# psc3_p8 register map
Vendor: Infineon Technologies; Series: PSC3_P8; File version: 1.0
CPU: CM33 r0p1, little endian, MPU, FPU, DSP, VTOR, 3 interrupt priority bits, 143 interrupts
Registers are 32-bit, read-write, reset 0x0 unless marked. A register's access mark holds for its fields unless they carry their own. Offsets are from the block's base; [hi:lo] are bit positions; lines under a group give offsets from that group; {n}, {i} and the like mark numbered series.

## PPCA_CPUSS_CNFG
Base 0x43080000
{0x0+0x10000*i} PPCA_MXCM33[{i}] (i=0..1) group — MXCM33-0/1
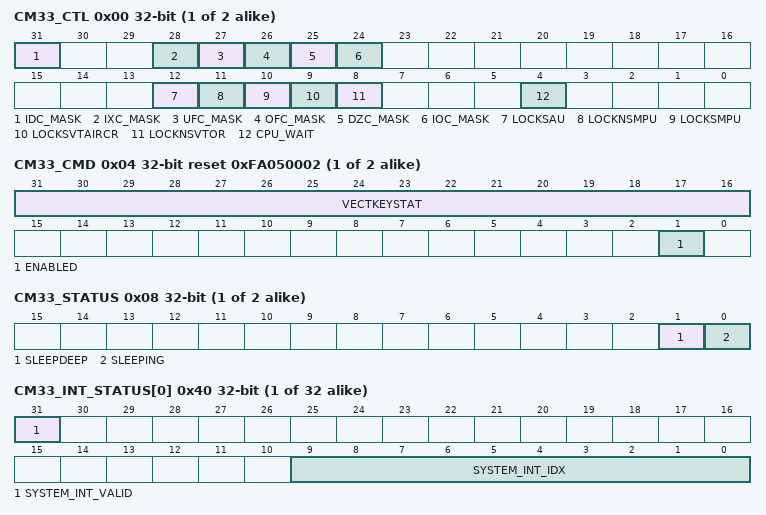
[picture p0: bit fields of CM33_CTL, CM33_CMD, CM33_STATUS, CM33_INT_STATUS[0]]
  0x00 CM33_CTL — Control
    [31] IDC_MASK
    [28] IXC_MASK
    [27] UFC_MASK
    [26] OFC_MASK
    [25] DZC_MASK
    [24] IOC_MASK — CPU floating point unit (FPU) exception mask for the CPU's FPCSR.IOC 'invalid operation' exception condition: '0': The CPU's exception condition does NOT activate the CPU's floating point interrupt. '1': the CPU's exception condition activates the CPU's floating point interrupt. Note: the ARM architecture does NOT support FPU exceptions; i.e. there is no precise FPU exception handler. Instead, FPU conditions are captured in the CPU's FPCSR register and the conditions are provided as CPU interface signals. The interface signals are 'masked' with the fields provided by this register (CM33_CTL). The 'masked' signals are reduced/OR-ed into a single CPU floating point interrupt signal. The associated CPU interrupt handler allows for imprecise handling of FPU exception conditions. Note: the CPU's FPCSR exception conditions are 'sticky'. Typically, the CPU FPU interrupt handler will clear the exception condition(s) to '0'. Note: by default, the FPU exception masks are '0'. Therefore, FPU exception conditions will NOT activate the CPU's floating point interrupt.
    [12] LOCKSAU
    [11] LOCKNSMPU
    [10] LOCKSMPU
    [9] LOCKSVTAIRCR
    [8] LOCKNSVTOR
    [4] CPU_WAIT
  0x04 CM33_CMD reset 0xFA050002 — Command
    [31:16] VECTKEYSTAT ro — Register key (to prevent accidental writes). - Should be written with a 0x05fa key value for the write to take effect. - Always reads as 0xfa05.
    [1] ENABLED — Processor enable: '0': Disabled. Processor clock is turned off and reset is activated. After SW clears this field to '0', HW automatically sets this field to '1'. This effectively results in a CM33 reset, followed by a CM33 warm boot. '1': Enabled. Note: The intent is that this bit is modified only through an external probe or by the other CM33 while this CM33 is in Sleep or DeepSleep power mode. If this field is cleared to '0' by this CM33 itself, it should be done under controlled conditions (such that undesirable side effects can be prevented). Note: The CM33 CPU has a AIRCR.SYSRESETREQ register field that allows the CM33 to reset the complete device (ENABLED only disables/enables the CM33), resulting in a warm boot. This CPU register field has similar 'built-in protection' as this register to prevent accidental system writes (the upper 16-bits of the register need to be written with a 0x05fa key value; see CPU user manual for more details).
  0x08 CM33_STATUS ro — Status
    [1] SLEEPDEEP — Specifies if the CPU is in Sleep or DeepSleep power mode. See SLEEPING field.
    [0] SLEEPING — Specifies if the CPU is in Active, Sleep or DeepSleep power mode: - Active power mode: SLEEPING is '0'. - Sleep power mode: SLEEPING is '1' and SLEEPDEEP is '0'. - DeepSleep power mode: SLEEPING is '1' and SLEEPDEEP is '1'.
  {0x40+4j} CM33_INT_STATUS[{j}] (j=0..15) ro (reset mask 0x80000000) — CM33 interrupt status
    [31] SYSTEM_INT_VALID — Valid indication for SYSTEM_INT_IDX. When '0', no system interrupt for CPU interrupt 0 is valid/activated.
    [9:0] SYSTEM_INT_IDX — Lowest CM33 activated system interrupt index for given CPU interrupt. Multiple system interrupts can be mapped on the same CPU interrupt. The selected system interrupt is the system interrupt with the lowest system interrupt index that has an activated interrupt request at the time of the fetch (system_interrupts[SYSTEM_INT_IDX] is '1'). The CPU interrupt handler SW can read SYSTEM_INT_IDX to determine the system interrupt that activated the handler.
  {0x80+4j} CM33_NMI_CTL[{j}] (j=0..3) reset 0x3FF — CM33 NMI control
    [9:0] SYSTEM_INT_IDX — System interrupt select for CPU NMI. The reset value ('1023') ensures that the CPU NMI is NOT connected to any system interrupt after DeepSleep reset.
  0xC0 CM33_EVENT_CTL — CM33 event control
    [4:0] MASK — One mask bit for each CPU (other than itself). 0: Mask is not set. 1: RX event from the corresponding CPU is masked. Bit 0: Other CM33 CPU event Bit 1: CM55_0 CPU event Bit 2: CM55_1 CPU event Bit 3: CM55_2 CPU event Bit 4: CM55_3 CPU event
  0x1000 CM33_S_VECTOR_TABLE_BASE — CM33 secure vector table base
    [31:7] ADDR25 — Address of CM33 secure vector table to be used at reset. Default value: ADDR25: 0x0200000 if PROM is present (points to Secure ROM start address i.e. 0x1000_0000). ADDR25: 0x0680000 if PROM is not present (points to Secure RAMC0 start address i.e. 0x3400_0000).
  0x1004 CM33_NS_VECTOR_TABLE_BASE — CM33 non-secure vector table base
    [31:7] ADDR25 — Address of CM33 non-secure vector table to be used at reset. Default value: ADDR25: 0x0000000 if PROM is present (points to Non-Secure ROM start address i.e. 0x0000_0000). ADDR25: 0x0480000 if PROM is not present (points to Non-Secure RAMC0 start address i.e. 0x2400_0000).
  0x2000 CM33_PC_CTL — CM33 protection context control
    [3:0] VALID — Valid fields for the protection context handler CM33_PCi_HANDLER registers: Bit 0: Valid field for CM33_PC0_HANDLER. Bit 1: Valid field for CM33_PC1_HANDLER. Bit 2: Valid field for CM33_PC2_HANDLER. Bit 3: Valid field for CM33_PC3_HANDLER.
  0x2040 CM33_PC0_HANDLER — CM33 protection context 0 handler
    [31:0] ADDR — Address of the protection context 0 handler. This field is used to detect entry to Cypress 'trusted' code through an exception/interrupt.
  {0x20C0+0x40*j} CM33_PC{j}_HANDLER (j=1..3) — CM33 protection context {j} handler
    [31:0] ADDR — Address of the protection context {j} handler.
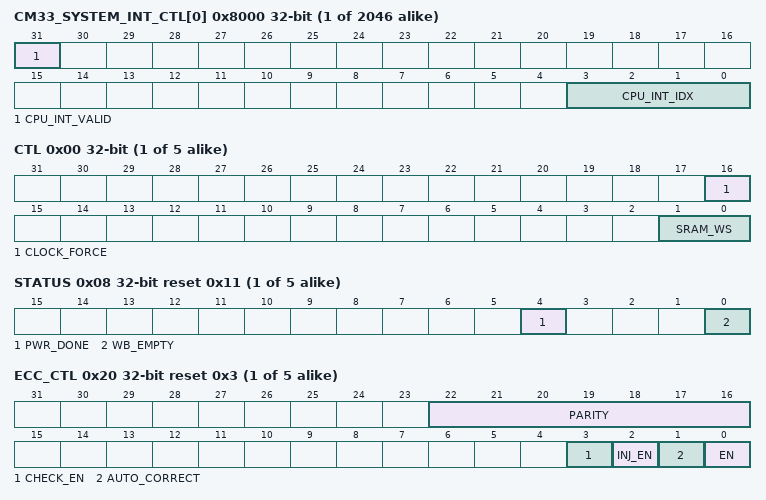
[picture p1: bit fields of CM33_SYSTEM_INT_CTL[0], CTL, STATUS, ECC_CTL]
  {0x8000+4j} CM33_SYSTEM_INT_CTL[{j}] (j=0..1022) (reset mask 0x80000000) — CM33 system interrupt control
    [31] CPU_INT_VALID — Interrupt enable: '0': Disabled. The system interrupt will NOT be mapped to any CPU interrupt. '1': Enabled. The system interrupt is mapped on CPU interrupt CPU_INT_IDX. Note: the CPUs have dedicated XXX_SYSTEM_INT_CTL registers. In other words, the CPUs can use different CPU interrupts for the same system interrupt. However, typically only one of the CPUs will have the ENABLED field of a specific system interrupt set to '1'.
    [3:0] CPU_INT_IDX — CPU interrupt index (legal range [0, 15]). This field specifies to which CPU interrupt the system interrupt is mapped. E.g., if CPU_INT_IDX is '6', the system interrupt is mapped to CPU interrupt '6'. Note: it is possible to map multiple system interrupts to the same CPU interrupt. It is advised to assign different priorities to the CPU interrupts and to assign system interrupts to CPU interrupts accordingly. Note: CPU_INT_IDX register width is derived from mxcm33 parameter IRQ_IDX_WIDTH. IRQ_IDX_WIDTH = (CM33_INT_NR == 16) ? 4 : 3
{0x20000+0x10000*i} RAMC[{i}] (i=0..4) group — RAMC0/1/2
  0x00 CTL — Control
    [16] CLOCK_FORCE — Force EAM clock gating to be always ON. 0: Disabled 1: Enabled This bit provides fail safe mechanism for dynamic clock gating added on EAM block.
    [1:0] SRAM_WS — Wait states.
      {v}=WS_{v} (N/A) (v=0..3)
  0x08 STATUS ro reset 0x11
    [4] PWR_DONE — After a PWR_MACRO_CTL.OFF change this flag indicates if the new power mode has taken effect or not. 1: Indicates change is effective; 0: Indicates change is in progress;
    [0] WB_EMPTY — Write buffer empty. This information is used when entering DeepSleep power mode: WB_EMPTY must be '1' before a transition to system DeepSleep power mode. '0': Write buffer NOT empty. '1': Write buffer empty. Note: the SRAM controller write buffer is only used when ECC checking is enabled. (RAMi_CTL.ECC_EN is '1').
  0x20 ECC_CTL reset 0x3 — ECC control
    [22:16] PARITY — Injected parity.
    [3] CHECK_EN — ECC checking enable: '0': Disabled. No ECC checking and associated bus errors. No fault reporting. Intended for SRAM initialization. '1': Enabled. Note: This field is ignored when EN is '0'.
    [2] INJ_EN — ECC parity injection: '0': Disabled. '1': Enabled. Instead of calculating the parity from the transfer's write data, the parity is taken from PARITY upon a match of the transfer's write address with ECC_MATCH.WORD_ADDR (no match is performed on the transfer's write strobes/mask). Note: Parity injection invalidates the write buffer for this word address. If only a part of 64-bit data word is written AND consistency should be maintained, STATUS.ALL_WB_EMPTY is '1' should be checked before. Note: This field is ignored when EN is '0'.
    [1] AUTO_CORRECT — ECC auto correction: '0': Disabled. Corrected ECC errors are ONLY HW corrected 'on-the-fly' (not corrected in the SRAM). Fault reporting is enabled. '1': Enabled. Correctable ECC errors are HW corrected 'on-the-fly' and in the SRAM, without CPU intervention. Fault reporting is enabled. Note: This field is ignored when EN is '0' or when CHECK_EN is '0'.
    [0] EN — ECC enable: '0': Disabled. '1': Enabled.
      0=ECC_DISABLED (N/A); 1=ECC_ENABLED (N/A)
  0x24 ECC_STATUS0 ro reset not defined
    [31:0] ADDR — ECC error address. This register captures the address location when ECC error happens.
  0x28 ECC_STATUS1 ro reset not defined
    [6:0] SYNDROME — This register captures the ECC syndrome when ECC error happens.
  0x104 ECC_MATCH
    [24:0] WORD_ADDR — Specifies the word address where an error will be injected. - On a write transfer to this SRAM address and when the ECC_CTL.INJ_EN bit is '1', the parity (ECC_CTL.PARITY) is injected.
  0x200 PWR_MACRO_CTL — SRAM power partition power control
    [31:0] OFF — Each bit represent the individual RAM power partition power state. One bit for each macro of RAM controller when all 32 bits are populated as 32 independent power partitions. 0: Macros in power partion is to be powered-ON 1: Macros in power partion is to be powered-OFF Note 1: it is not allowed to disable a macro during access to its address range. Note 2: it is not allowed to disable few macros while enable others in the same AHB write transaction. It is mandatory to check for STATUS.PWR_DONE to become 1 once this PWR_MACRO_DTL register contents are changed to ensure SRAM mode transition is completed successfully.
  0x240 PWR_MACRO_CTL_LOCK reset 0x3 — SRAM power partition power control Lock
    [1:0] PWR_MACRO_CTL_LOCK — Prohibits Read/Write access to PWR_MACRO_CTL register when this field is not equal to 0. Requires at least two different writes to unlock. Note that this field is 2 bits to force multiple writes only. By default AHB reads/writes to PWR_MACRO_CTL register are locked.
      0=NO_CHG (No effect); 1=CLR0 (Clears bit 0); 2=CLR1 (Clears bit 1); 3=SET01 (Sets both bits 0 and 1)
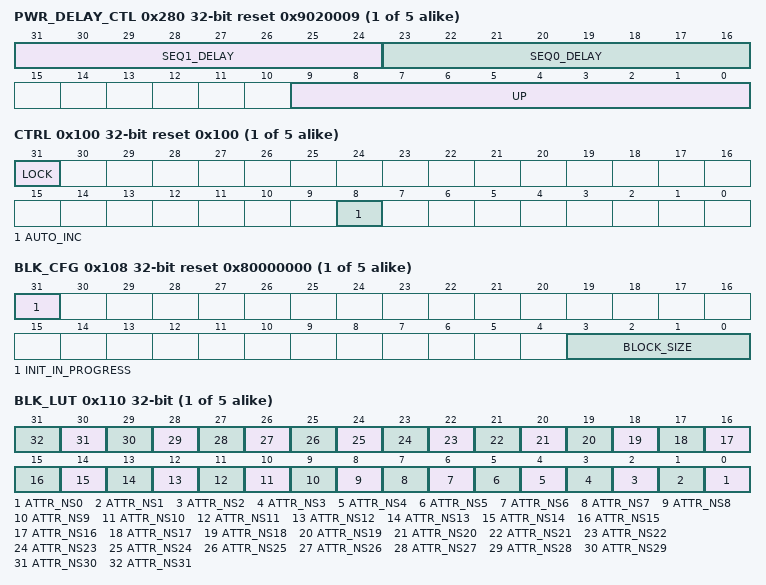
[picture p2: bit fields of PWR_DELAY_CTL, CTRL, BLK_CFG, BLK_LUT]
  0x280 PWR_DELAY_CTL reset 0x9020009 — SRAM power switch power up & sequence delay
    [31:24] SEQ1_DELAY — Number of IMO clock cycles delay needed for sequence-1 of SRAM power transition
    [23:16] SEQ0_DELAY — Number of IMO clock cycles delay needed for sequence-0 of SRAM power transition
    [9:0] UP — Number of IMO clock cycles delay needed after power domain power up
  0x4000 MPC group — MPC Memory Protection Controller registers
    0x00 CFG — Config register with error response, RegionID PPC_MPC_MAIN is the security owner PC. The error response configuration is located in CFG.RESPONSE, only one such configuration exists applying to all protection contexts in the system.
      [4] RESPONSE — Response Configuration for Security and PC violations 0: Read-Zero Write Ignore (RAZ/WI) 1: Bus Error
    0x100 CTRL reset 0x100 — Control register with lock bit and auto-increment only (Separate CTRL for each PC depends on access_pc)
      [31] LOCK write-1-sets — Security lockdown for this protection context. Software can set this bit but not clear it once set. When set, write operations to BLK_LUT are not possible from this protection context. Setting LOCK also blocks writes to CTRL itself (for that PC copy). All writes are ignored.
      [8] AUTO_INC — Auto-increment BLK_IDX by 1 for this protection context as a side effect of each read/write access to BLK_LUT
    0x104 BLK_MAX ro — Max value of block-based index register
      [31:0] VALUE — Maximum value of block-based index register. The number and size blocks in an MPC is design time configurable and for embedded memories defaults to covering the entire memory using 4kB blocks; See product datasheet for details on protection of external memories.
    0x108 BLK_CFG ro reset 0x80000000 — Block size & initialization in progress
      [31] INIT_IN_PROGRESS — During initialization INIT_IN_PROGRESS is '1' and MMIO register accesses to BLK_LUT is blocked (BLK_IDX increment is also ignored). The block attributes are retained in DeepSleep (and obviously Active) power mode. Initialization is only required from a power mode in which the block attributes are not retained. E.g., initialization is required for a cold boot (after a Power-on-Reset). HW initializes the block attributes: the NS attributes are set to '0' (secure), the R attributes are set to '1' (read access allowed) and the W attributes are set to '1' (write access allowed). During initialization, the MPC supports memory accesses (memory accesses are NOT blocked) with the initialization block attribute values as mentioned above. This e.g. allows MPC initialization to proceed in parallel with boot program memory accesses (as opposed to serializing the two), improving device boot time.
      [3:0] BLOCK_SIZE — Block size of individually protected blocks (0: 32B, 1: 64B, ... up to 15: 1MB) Block size= (1<<(BLOCK_SIZE+5)) The number and size blocks in an MPC is design time configurable and for embedded memories defaults to covering the entire memory using 4kB blocks; see product datasheet for details on protection of external memories.
    0x10C BLK_IDX — Index of 32-block group accessed through BLK_LUT (Separate IDX for each PC depending on access_pc)
      [31:0] VALUE — Index value for accessing block-based lookup table using BLK_LUT. Programming out of LUT range is an user error and it loops back to '0' once overflow occurs.
    0x110 BLK_LUT — NS status for 32 blocks at BLK_IDX with PC=<access_pc>
      [n] ATTR_NS{n} (n=0..31) — NS bit for block {n} based on BLK_IDX
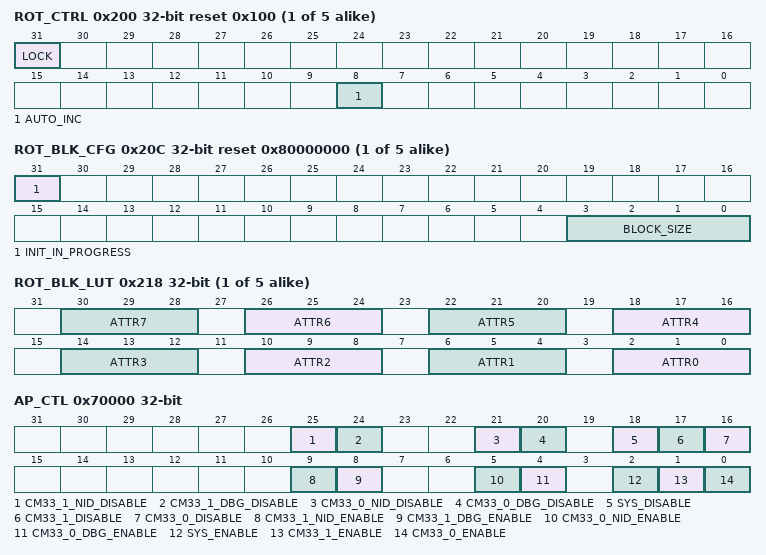
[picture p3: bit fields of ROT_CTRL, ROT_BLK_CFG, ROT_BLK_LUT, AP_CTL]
    0x200 ROT_CTRL reset 0x100 — Control register with lock bit and auto-increment only
      [31] LOCK write-1-sets — Security lockdown for the root-of-trust configuration registers. Software can set this bit but not clear it once set. When set, write operations to ROT_BLK_LUT are not possible. Write is ignored.
      [8] AUTO_INC — Auto-increment BLK_IDX by 1 for each read/write of ROT_BLK_LUT
    0x208 ROT_BLK_MAX ro — Max value of block-based index register for ROT
      [31:0] VALUE — Maximum value of block-based index register. The number and size blocks in an MPC is design time configurable and for embedded memories defaults to covering the entire memory using 4kB blocks; see product datasheet for details on protection of external memories.
    0x20C ROT_BLK_CFG ro reset 0x80000000 — Same as BLK_CFG
      [31] INIT_IN_PROGRESS — During initialization INIT_IN_PROGRESS is '1' and MMIO register accesses to ROT_BLK_LUT is RAZWI. The block attributes are retained in DeepSleep (and obviously Active) power mode. Initialization is only required from a power mode in which the block attributes are not retained. E.g., initialization is required for a cold boot (after a Power-on-Reset). HW initializes the block attributes: the NS attributes are set to '0' (secure), the R attributes are set to '1' (read access allowed) and the W attributes are set to '1' (write access allowed). During initialization, the MPC supports memory accesses (memory accesses are NOT blocked) with the initialization block attribute values as mentioned above. This e.g. allows MPC initialization to proceed in parallel with boot program memory accesses (as opposed to serializing the two), improving device boot time.
      [3:0] BLOCK_SIZE — Block size of individually protected blocks (0: 32B, 1: 64B, ...up to 15:1MB) Block size= (1<<(BLOCK_SIZE+5)) The number and size blocks in an MPC is design time configurable and for embedded memories defaults to covering the entire memory using 4kB blocks; see product datasheet for details on protection of external memories.
    0x210 ROT_BLK_IDX — Index of 8-block group accessed through ROT_BLK_LUT_*
      [31:0] VALUE — Index value for accessing block-based lookup table using ROT_BLK_LUT. Programming out of LUT range is an user error and it loops back to '0' once overflow occurs.
    0x214 ROT_BLK_PC — Protection context of 8-block group accesses through ROT_BLK_LUT
      [3:0] PC — Specify PC values for ROT_BLK_IDX and ROT_BLK_LUT
    0x218 ROT_BLK_LUT — (R,W,NS) bits for 8 blocks at ROT_BLK_IDX for PC=ROT_BKL_PC
      [4n+2:4n] ATTR{n} (n=0..7) — W/R/NS bits for block {n} indicated by ROT_BLK_IDX for ROT_BLK_PC PC
0x70000 AP_CTL — Access port control
  [25] CM33_1_NID_DISABLE write-1-sets — Refer CM33_0_NID_DISABLE description.
  [24] CM33_1_DBG_DISABLE write-1-sets — Refer CM33_0_DBG_DISABLE description.
  [21] CM33_0_NID_DISABLE write-1-sets — Disable Non-invasive debug for CM33_0. '1': Disables all trace and non-invasive debug features. '0': Enables all trace and non-invasive debug features. Typically, this field is set by the Cypress boot code with information from eFUSE. The non-invasive debug is only enabled when CM33_0_NID_DISABLE is '0' and CM33_0_NID_ENABLE is '1'.
  [20] CM33_0_DBG_DISABLE write-1-sets — Disable Invasive debug for CM33_0. '1': Disables all halt-mode and invasive debug features. '0': Enables invasive debug features. Typically, this field is set by the Cypress boot code with information from eFUSE. The invasive debug is only enabled when CM33_0_DBG_DISABLE is '0' and CM33_0_DBG_ENABLE is '1'.
  [18] SYS_DISABLE write-1-sets — Disables the system AP interface: '0': Enabled. '1': Disabled. Typically, this field is set by the Cypress boot code with information from eFUSE. The access port is only enabled when SYS_DISABLE is '0' and SYS_ENABLE is '1'.
  [17] CM33_1_DISABLE write-1-sets — Disables the CM33_1 AP interface: '0': Enabled. '1': Disabled. Typically, this field is set by the Cypress boot code with information from eFUSE. The access port is only enabled when CM33_DISABLE is '0' and CM33_ENABLE is '1'.
  [16] CM33_0_DISABLE write-1-sets — Disables the CM33_0 AP interface: '0': Enabled. '1': Disabled. Typically, this field is set by the Cypress boot code with information from eFUSE. The access port is only enabled when CM0_DISABLE is '0' and CM0_ENABLE is '1'.
  [9] CM33_1_NID_ENABLE — Refer CM33_0_NID_ENABLE.
  [8] CM33_1_DBG_ENABLE — Refer CM33_0_DBG_ENABLE.
  [5] CM33_0_NID_ENABLE — Non-invasive debug enable for CM33_0. '0': Disables all trace and non-invasive debug features. '1': Enables all trace and non-invasive debug features.
  [4] CM33_0_DBG_ENABLE — Invasive debug enable for CM33_0. '0': Disables all halt-mode and invasive debug features. '1': Enables invasive debug features.
  [2] SYS_ENABLE — Enables the system AP interface: '0': Disabled. '1': Enabled.
  [1] CM33_1_ENABLE — Enables the CM33_1 AP interface: '0': Disabled. '1': Enabled.
  [0] CM33_0_ENABLE — Enables the CM33_0 AP interface: '0': Disabled. '1': Enabled.
0x70004 MP_CTL — Master Port Access control
  [0] PPCA_MS_TIMEOUT_ENABLE — Enables the PPCA Master Port Timeout Access control: '0': Disabled. '1': Enabled.
{0x78000+0x1000*i} RAMC_PPU[{i}] (i=0..4) group — Power Policy Unit Registers for System RAM
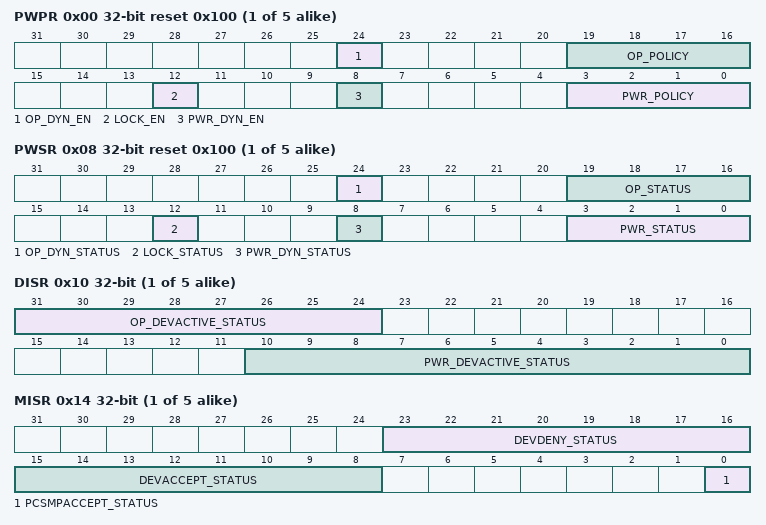
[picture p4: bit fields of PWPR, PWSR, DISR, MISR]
  0x00 PWPR reset 0x100 — Power Policy Register
    [24] OP_DYN_EN
    [19:16] OP_POLICY
    [12] LOCK_EN
    [8] PWR_DYN_EN — Power mode dynamic transition enable. When this bit is set to 1 dynamic transitions are enabled for power modes, allowing transitions to be initiated by changes on power mode DEVACTIVE inputs.
    [3:0] PWR_POLICY — Power mode policy. When static power mode transitions are enabled, PWR_DYN_EN is set to 0, this is the target power mode for the PPU. When dynamic power mode transitions are enabled, PWR_DYN_EN is set to 1, this is the minimum power mode for the PPU. This PPU supports the following modes: OFF(0), MEM_RET(2), ON(8). Do not use WARM_RST(9) or other unsupported modes.
  0x04 PMER — Power Mode Emulation Register
    [0] EMU_EN
  0x08 PWSR ro reset 0x100 — Power Status Register
    [24] OP_DYN_STATUS
    [19:16] OP_STATUS
    [12] LOCK_STATUS
    [8] PWR_DYN_STATUS — Power mode dynamic transition status. When set to 1 power mode dynamic transitions are enabled. There might be a delay in dynamic transitions becoming active or inactive if the PPU is transitioning when PWR_DYN_EN is programmed.
    [3:0] PWR_STATUS — Power mode status. These bits reflect the current power mode of the PPU. See PPU_PWPR.PWR_POLICY for power mode enumeration.
  0x10 DISR ro — Device Interface Input Current Status Register
    [31:24] OP_DEVACTIVE_STATUS
    [10:0] PWR_DEVACTIVE_STATUS — Status of the power mode DEVACTIVE inputs. There is one bit for each device interface Q-Channel DEVQACTIVE. For example, bit 0 is for Q-channel device 0 DEVQACTIVE. Refer to PPU_IDR0.DEVCHAN for device channel enumeration.
  0x14 MISR ro — Miscellaneous Input Current Status Register
    [23:16] DEVDENY_STATUS — Status of the device interface DEVDENY inputs. There is one bit for each device interface DEVQDENY. For example, bit 16 is for Q-Channel 0 DEVQDENY, and bit 17 for Q-Channel 1 DEVQDENY. Refer to PPU_IDR0.DEVCHAN for device channel enumeration.
    [15:8] DEVACCEPT_STATUS — Status of the device interface DEVACCEPT inputs. There is one bit for each device interface DEVQACCEPTn. For example, bit 8 is for Q-Channel 0 DEVQACCEPTn and bit 9 for Q-Channel 1 DEVQACCEPTn. Refer to PPU_IDR0.DEVCHAN for device channel enumeration.
    [0] PCSMPACCEPT_STATUS — The status of the PCSMPACCEPT input.
  0x18 STSR ro — Stored Status Register
    [7:0] STORED_DEVDENY
  0x1C UNLK — Unlock register
    [0] UNLOCK
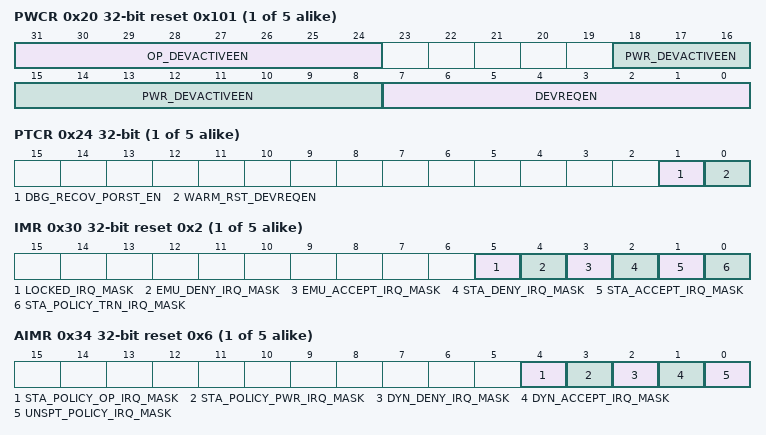
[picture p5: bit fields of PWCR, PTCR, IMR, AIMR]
  0x20 PWCR reset 0x101 — Power Configuration Register
    [31:24] OP_DEVACTIVEEN
    [18:8] PWR_DEVACTIVEEN — These bits enable the power mode DEVACTIVE inputs. When a bit is to 1 the related DEVACTIVE input is enabled, when set to 0 it is disabled. All available bits are reset to 1. There is one bit for each device interface Q-Channel DEVQACTIVE. For example, bit 8 is for the Q-Channel 0 DEVQACTIVE, and bit 9 for the Q-Channel 1 DEVQACTIVE. Refer to PPU_IDR0.DEVCHAN for device channel enumeration.
    [7:0] DEVREQEN — When set to 1 enables the device interface handshake for transitions. All available bits are reset to 1. There is one bit for each device interface channel. For example, bit 0 is for Q-Channel 0, and bit 1 is for Q-Channel 1. Refer to PPU_IDR0.DEVCHAN for device channel enumeration.
  0x24 PTCR — Power Mode Transition Configuration Register
    [1] DBG_RECOV_PORST_EN
    [0] WARM_RST_DEVREQEN — Transition behavior between ON and WARM_RST. This bit should not be modified when the PPU is in WARM_RST, or if the PPU is performing a transition, otherwise PPU behavior is UNPREDICTABLE. 0: The PPU does not perform a device interface handshake when transitioning between ON and WARM_RST. 1: The PPU performs a device interface handshake when transitioning between ON and WARM_RST. This disables all Q-Channels for this transition.
  0x30 IMR reset 0x2 — Interrupt Mask Register
    [5] LOCKED_IRQ_MASK
    [4] EMU_DENY_IRQ_MASK
    [3] EMU_ACCEPT_IRQ_MASK
    [2] STA_DENY_IRQ_MASK — Static transition denial event mask.
    [1] STA_ACCEPT_IRQ_MASK — Static transition acceptance event mask.
    [0] STA_POLICY_TRN_IRQ_MASK — Static full policy transition completion event mask.
  0x34 AIMR reset 0x6 — Additional Interrupt Mask Register
    [4] STA_POLICY_OP_IRQ_MASK
    [3] STA_POLICY_PWR_IRQ_MASK
    [2] DYN_DENY_IRQ_MASK — Dynamic transition denial event mask.
    [1] DYN_ACCEPT_IRQ_MASK — Dynamic transition acceptance event mask.
    [0] UNSPT_POLICY_IRQ_MASK — Unsupported Policy event mask.
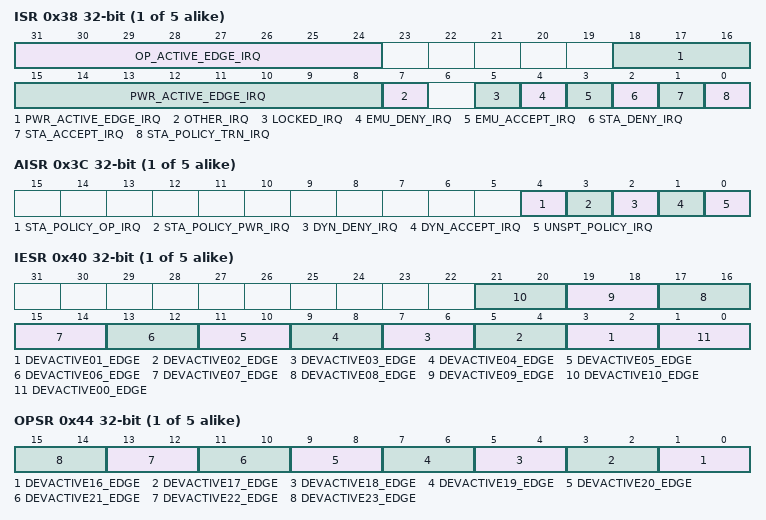
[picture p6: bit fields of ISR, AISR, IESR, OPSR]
  0x38 ISR — Interrupt Status Register
    [31:24] OP_ACTIVE_EDGE_IRQ write-1-clears
    [18:8] PWR_ACTIVE_EDGE_IRQ write-1-clears
    [7] OTHER_IRQ ro — Indicates there is an interrupt event pending in the Additional Interrupt Status Register (PPU_AISR).
    [5] LOCKED_IRQ write-1-clears
    [4] EMU_DENY_IRQ write-1-clears
    [3] EMU_ACCEPT_IRQ write-1-clears
    [2] STA_DENY_IRQ write-1-clears — Static transition denial event status.
    [1] STA_ACCEPT_IRQ write-1-clears — Static transition acceptance event status.
    [0] STA_POLICY_TRN_IRQ write-1-clears — Static full policy transition completion event status.
  0x3C AISR — Additional Interrupt Status Register
    [4] STA_POLICY_OP_IRQ write-1-clears
    [3] STA_POLICY_PWR_IRQ write-1-clears
    [2] DYN_DENY_IRQ write-1-clears — Dynamic transition denial event status.
    [1] DYN_ACCEPT_IRQ write-1-clears — Dynamic transition acceptance event status.
    [0] UNSPT_POLICY_IRQ write-1-clears — Unsupported Policy event status.
  0x40 IESR — Input Edge Sensitivity Register
    [2n+1:2n] DEVACTIVE{n:02}_EDGE (n=1..10)
    [1:0] DEVACTIVE00_EDGE — DEVACTIVE 0 edge sensitivity.
  0x44 OPSR — Operating Mode Active Edge Sensitivity Register
    [2n-31:2n-32] DEVACTIVE{n}_EDGE (n=16..23)
  0x50 FUNRR — Functional Retention RAM Configuration Register
    [7:0] FUNC_RET_RAM_CFG
  0x54 FULRR — Full Retention RAM Configuration Register
    [7:0] FULL_RET_RAM_CFG
  0x58 MEMRR — Memory Retention RAM Configuration Register
    [7:0] MEM_RET_RAM_CFG
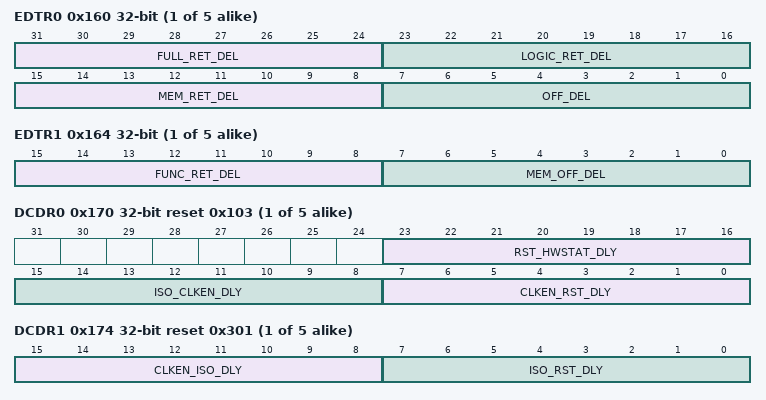
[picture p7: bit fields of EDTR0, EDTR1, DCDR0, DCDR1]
  0x160 EDTR0 — Power Mode Entry Delay Register 0
    [31:24] FULL_RET_DEL, [23:16] LOGIC_RET_DEL, [15:8] MEM_RET_DEL, [7:0] OFF_DEL
  0x164 EDTR1 — Power Mode Entry Delay Register 1
    [15:8] FUNC_RET_DEL, [7:0] MEM_OFF_DEL
  0x170 DCDR0 ro reset 0x103 — Device Control Delay Configuration Register 0
    [23:16] RST_HWSTAT_DLY, [15:8] ISO_CLKEN_DLY, [7:0] CLKEN_RST_DLY
  0x174 DCDR1 ro reset 0x301 — Device Control Delay Configuration Register 1
    [15:8] CLKEN_ISO_DLY, [7:0] ISO_RST_DLY
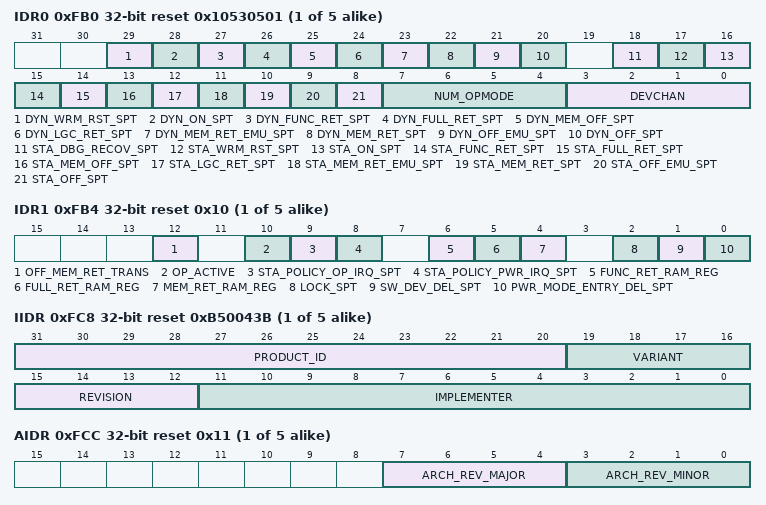
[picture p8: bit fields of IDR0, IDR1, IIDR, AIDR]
  0xFB0 IDR0 ro reset 0x10530501 — PPU Identification Register 0
    [29] DYN_WRM_RST_SPT — Dynamic WARM_RST support.
    [28] DYN_ON_SPT — Dynamic ON support.
    [27] DYN_FUNC_RET_SPT — Dynamic FUNC_RET support.
    [26] DYN_FULL_RET_SPT — Dynamic FULL_RET support.
    [25] DYN_MEM_OFF_SPT — Dynamic MEM_OFF support.
    [24] DYN_LGC_RET_SPT — Dynamic LOGIC_RET support.
    [23] DYN_MEM_RET_EMU_SPT — Dynamic MEM_RET_EMU support
    [22] DYN_MEM_RET_SPT — Dynamic MEM_RET support.
    [21] DYN_OFF_EMU_SPT — Dynamic OFF_EMU support.
    [20] DYN_OFF_SPT — Dynamic OFF support.
    [18] STA_DBG_RECOV_SPT — DBG_RECOV support.
    [17] STA_WRM_RST_SPT — WARM_RST support. Ignore this bit. Do not use WARM_RST.
    [16] STA_ON_SPT — ON support.
    [15] STA_FUNC_RET_SPT — FUNC_RET support.
    [14] STA_FULL_RET_SPT — FULL_RET support.
    [13] STA_MEM_OFF_SPT — MEM_OFF support.
    [12] STA_LGC_RET_SPT — LOGIC_RET support.
    [11] STA_MEM_RET_EMU_SPT — MEM_RET_EMU support.
    [10] STA_MEM_RET_SPT — MEM_RET support.
    [9] STA_OFF_EMU_SPT — OFF_EMU support.
    [8] STA_OFF_SPT — OFF support.
    [7:4] NUM_OPMODE — No. of operating modes supported is NUM_OPMODE + 1.
    [3:0] DEVCHAN — No. of Device Interface Channels. The device enumeration is: Device 0: PDCM
  0xFB4 IDR1 ro reset 0x10 — PPU Identification Register 1
    [12] OFF_MEM_RET_TRANS — OFF to MEM_RET direct transition. Indicates if direct transitions from OFF to MEM_RET and from OFF_EMU to MEM_RET_EMU are supported.
    [10] OP_ACTIVE
    [9] STA_POLICY_OP_IRQ_SPT — Operating policy transition completion event status.
    [8] STA_POLICY_PWR_IRQ_SPT — Power policy transition completion event status.
    [6] FUNC_RET_RAM_REG
    [5] FULL_RET_RAM_REG
    [4] MEM_RET_RAM_REG
    [2] LOCK_SPT — Lock and the lock interrupt event are supported.
    [1] SW_DEV_DEL_SPT — Software device delay control configuration support.
    [0] PWR_MODE_ENTRY_DEL_SPT — Power mode entry delay support.
  0xFC8 IIDR ro reset 0xB50043B — Implementation Identification Register
    [31:20] PRODUCT_ID — PPU part identification.
    [19:16] VARIANT — Major revision of the product.
    [15:12] REVISION — Minor revision of the product.
    [11:0] IMPLEMENTER — Implementer identification. [11:8] The JEP106 continuation code of the implementer. [7] Always 0. [6:0] The JEP106 identity code of the implementer. For an Arm implementation, bits [11:0] are 0x43B.
  0xFCC AIDR ro reset 0x11 — Architecture Identification Register
    [7:4] ARCH_REV_MAJOR, [3:0] ARCH_REV_MINOR
  0xFD0 PID4 ro reset 0x4 — Implementation Defined Identification Register (PID4)
    [3:0] IMPLEMENTER_11_8 — The JEP106 continuation code of the implementer, which is 0x4 hardcoded value.
  0xFE0 PID0 ro reset 0xB5 — Implementation Defined Identification Register (PID0)
    [7:0] PRODUCT_ID_7_0 — PPU part identification bits [7:0].
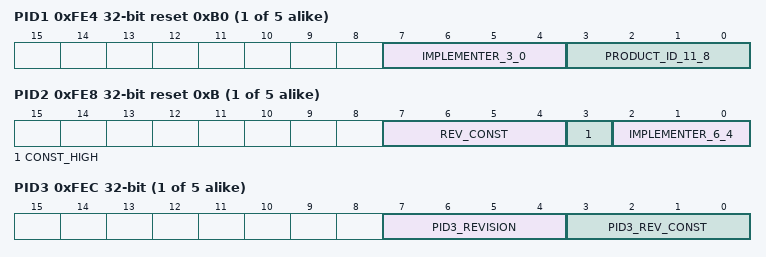
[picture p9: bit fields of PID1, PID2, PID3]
  0xFE4 PID1 ro reset 0xB0 — Implementation Defined Identification Register (PID1)
    [7:4] IMPLEMENTER_3_0 — JEP106_ID bits [3:0]
    [3:0] PRODUCT_ID_11_8 — PPU part identification bits [11:8]
  0xFE8 PID2 ro reset 0xB — Implementation Defined Identification Register (PID2)
    [7:4] REV_CONST — Constant LOW Revision (4 bits)
    [3] CONST_HIGH — Constant HIGH
    [2:0] IMPLEMENTER_6_4 — JEP106_ID bits [6:4]
  0xFEC PID3 ro — Implementation Defined Identification Register (PID3)
    [7:4] PID3_REVISION — Minor revision of the product.
    [3:0] PID3_REV_CONST — Constant LOW (4 bits)
  0xFF0 ID0 ro reset 0xD — Implementation Defined Identification Register (ID0)
    [7:0] ID0 — ID0 hard coded value
  0xFF4 ID1 ro reset 0xF0 — Implementation Defined Identification Register (ID1)
    [7:0] ID1 — ID1 hardcoded value
  0xFF8 ID2 ro reset 0x5 — Implementation Defined Identification Register (ID2)
    [7:0] ID2 — ID2 hardcoded value
  0xFFC ID3 ro reset 0xB1 — Implementation Defined Identification Register (ID3)
    [7:0] ID3 — ID3 hardcoded value
